# RTS591x register map
Vendor: Realtek Semiconductor Corp.; Series: RTS591x Series; File version: 1.0
CPU: ARMV8MML r0p0, little endian, MPU, FPU, VTOR, 3 interrupt priority bits, 4 SAU regions
Registers are 32-bit, read-write, reset 0x0 unless marked. A register's access mark holds for its fields unless they carry their own. Offsets are from the block's base; [hi:lo] are bit positions; {n}, {i} and the like mark numbered series.

## ADC — 12-bit ADC Controller
Base 0x4000FE00
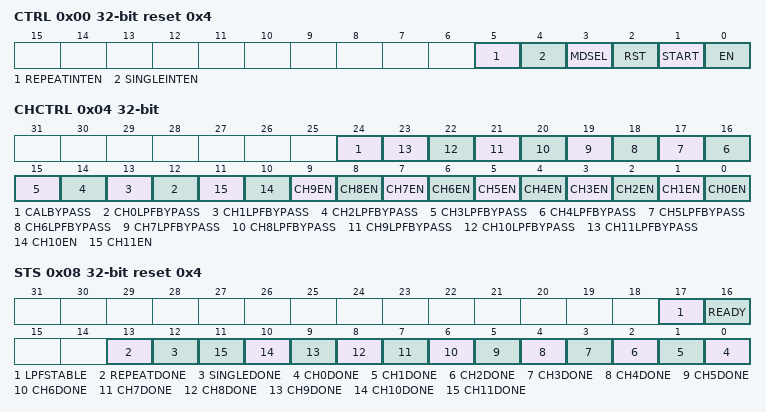
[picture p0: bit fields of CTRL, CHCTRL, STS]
0x00 CTRL reset 0x4 — CONTROL REGISTER
  [5] REPEATINTEN — Enable Repeat Done Interrupt
    0=DISABLE (Disable repeat done interrupt); 1=ENABLE (Enable repeat done interrupt)
  [4] SINGLEINTEN — Enable Single Done Interrupt
    0=DISABLE (Disable single done interrupt); 1=ENABLE (Enable single done interrupt)
  [3] MDSEL — Conversion Mode Selection
    0=SINGLE_MODE (Performed ADC conversion only one time); 1=REPEAT_MODE (Performed ADC conversions continuously)
  [2] RST — Reset ADC Controller
    0=RESET (Hold ADC controller in reset stage); 1=ACTIVE (ADC controller is in active stage)
  [1] START — Start ADC conversion
    0=DO_NOTHING; 1=START (Start ADC scan conversions)
  [0] EN — Enable ADC controller
    0=DISABLE (Disable ADC controller); 1=ENABLE (Enable ADC controller)
0x04 CHCTRL — CHANNEL CONTROL REGISTER
  [24] CALBYPASS — Bypass ADC Channel Linear Calibration
    0=THROUGH (Through linear calibration); 1=BYPASS (Bypass linear calibration)
  [n+12] CH{n}LPFBYPASS (n=0..11) — Bypass ADC Channel Low-Pass Filter
    0=THROUGH (Through low-pass filter); 1=BYPASS (Bypass low-pass filter)
  [n] CH{n}EN (n=0..11) — Enable ADC Channel
    0=DISABLE (Disable ADC channel); 1=ENABLE (Enable ADC channel)
0x08 STS reset 0x4 — STATUS REGISTER
  [17] LPFSTABLE ro — Low-Pass Filter Stable
    0=NOT_STABLE (Low-pass filter data is not stable); 1=STABLE (Low-pass filter data is stable)
  [16] READY ro — Ready After Power-On
    0=NOT_READY (ADC is not ready to start after power-on); 1=READY (ADC is ready to start after power-on)
  [13] REPEATDONE — Repeat Conversion Complete
    0=NOT_FIN (Repeat conversion is not completed); 1=DONE (Repeat conversion is completed)
  [12] SINGLEDONE — Single Conversion Complete
    0=NOT_FIN (Single conversion is not completed); 1=DONE (Single conversion is completed)
  [n] CH{n}DONE (n=0..11) — Conversion of ADC Channel Complete
    0=NOT_FIN (Conversion of ADC channel0 is not complete); 1=DONE (Conversion of ADC channel0 is complete)
{0xC+4i} CHDATA[{i}] (i=0..10) — ADC channel[{i}] Data
  [11:0] DATA — Conversion data, measured by the A/D converter

## PS2 — PS2 Controller
Base 0x4000FF00
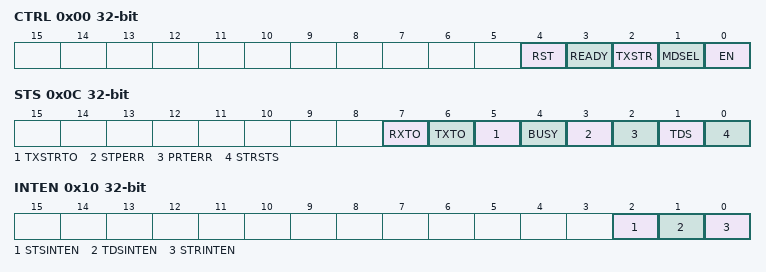
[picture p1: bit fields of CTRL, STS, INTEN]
0x00 CTRL — CONTROL REGISTER
  [4] RST — Reset PS/2 Controller
    0=RESET (Hold PS/2 controller in reset stage); 1=ACTIVE (PS/2 controller is in active stage)
  [3] READY ro — PS/2 Controller is Ready to Transmit
    0=NOT_READY (PS/2 controller is not ready to transmit); 1=READY (PS/2 controller is ready to transmit)
  [2] TXSTR — Kick PS/2 Controller Start to Transmit
  [1] MDSEL — Accessing Mode Selection
    0=RECEIVE (Set PS/2 controller to receive mode); 1=TRANSMIT (Set PS/2 controller to transmit mode)
  [0] EN — Enable PS/2 Controller
    0=DISABLE (Disable PS/2 Controller); 1=ENABLE (Enable PS/2 Controller)
0x04 TXDAT — TRANSMIT DATA REGISTER
  [7:0] DATA — PS/2 Transmit Data
0x08 RXDAT — RECEIVE DATA REGISTER
  [7:0] DATA — PS/2 Receive Data Buffer
0x0C STS — STATUS REGISTER
  [7] RXTO write-1-clears — Receive Timeout Status
    0=NOT_OCCURRED (Receive timeout is not occurred); 1=OCCURRED (Receive timeout is occurred)
  [6] TXTO write-1-clears — Transmit Timeout Status
    0=NOT_OCCURRED (Transmit timeout is not occurred); 1=OCCURRED (Transmit timeout is occurred)
  [5] TXSTRTO write-1-clears — Transmit Start Timeout Status
    0=NOT_OCCURRED (Transmit start timeout is not occurred); 1=OCCURRED (Transmit start timeout is occurred)
  [4] BUSY ro — Busy Status
  [3] STPERR write-1-clears — Stop-bit Error Status
    0=NOT_OCCURRED (Stop-bit error is not occurred); 1=OCCURRED (Stop-bit error is occurred)
  [2] PRTERR write-1-clears — Parity-bit Error Status
    0=NOT_OCCURRED (Parity-bit error is not occurred); 1=OCCURRED (Parity-bit error is occurred)
  [1] TDS write-1-clears — Transcation Done Status
    0=NOT_OCCURRED (Transcation done is not occurred); 1=OCCURRED (Transcation done is occurred)
  [0] STRSTS write-1-clears — Strat-bit Detection Status
    0=NOT_OCCURRED (Strat-bit detection is not occurred); 1=OCCURRED (Strat-bit detection is occurred)
0x10 INTEN — INTERRUPT ENABLE REGISTER
  [2] STSINTEN — Enable Status Interrupt
    0=DISABLE (Disable status interrupt); 1=ENABLE (Enable status interrupt)
  [1] TDSINTEN — Enable Transmit Done Interrupt
    0=DISABLE (Disable transmit done interrupt); 1=ENABLE (Enable transmit done interrupt)
  [0] STRINTEN — Enable Start-bit Detection Interrupt
    0=DISABLE (Disable start-bit detection interrupt); 1=ENABLE (Enable start-bit detection interrupt)
